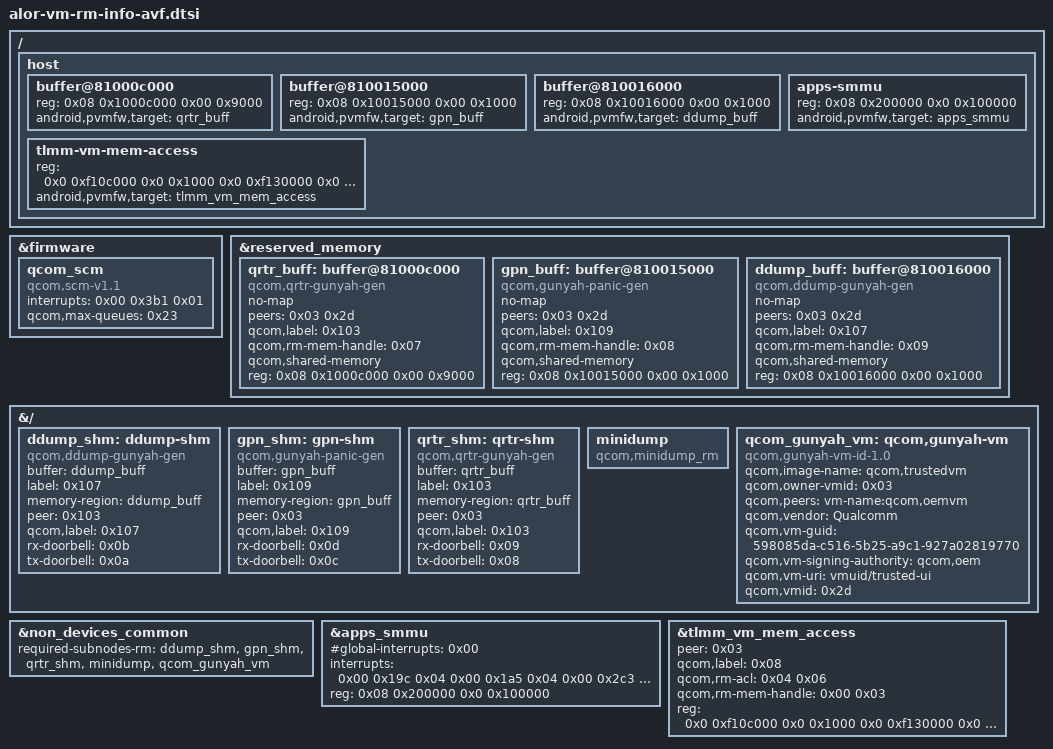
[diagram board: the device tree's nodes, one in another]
// SPDX-License-Identifier: BSD-3-Clause
/*
 * Copyright (c) Qualcomm Technologies, Inc. and/or its subsidiaries.
 */

/ {
	host {
		buffer@81000c000 {
			reg = <0x08 0x1000c000 0x00 0x9000>;
			android,pvmfw,target = <&qrtr_buff>;
		};

		buffer@810015000 {
			reg = <0x08 0x10015000 0x00 0x1000>;
			android,pvmfw,target = <&gpn_buff>;
		};

		buffer@810016000 {
			reg = <0x08 0x10016000 0x00 0x1000>;
			android,pvmfw,target = <&ddump_buff>;
		};

		apps-smmu {
			reg = <0x08 0x200000 0x0 0x100000>;
			android,pvmfw,target = <&apps_smmu>;
		};

		tlmm-vm-mem-access {
			reg = <0x0 0xf10c000 0x0 0x1000 0x0 0xf130000 0x0 0x1000 0x0 0xf131000 0x0 0x1000 0x0 0xf132000 0x0 0x1000 0x0 0xf133000 0x0 0x1000 0x0 0xf137000 0x0 0x1000 0x0 0xf144000 0x0 0x1000 0x0 0xf145000 0x0 0x1000 0x0 0xf146000 0x0 0x1000 0x0 0xf147000 0x0 0x1000 0x0 0xf156000 0x0 0x1000 0x0 0xf157000 0x0 0x1000 0x0 0xf158000 0x0 0x1000 0x0 0xf164000 0x0 0x1000 0x0 0xf180000 0x0 0x1000 0x0 0xf192000 0x0 0x1000 0x0 0xf1a1000 0x0 0x1000>;
			android,pvmfw,target = <&tlmm_vm_mem_access>;
		};
	};
};

&firmware {
	qcom_scm {
		compatible = "qcom,scm-v1.1", "qcom,scm";
		interrupts = <0x00 0x3b1 0x01>;
		qcom,max-queues = <0x23>;
	};

};

&reserved_memory {

	qrtr_buff: buffer@81000c000 {
		compatible = "qcom,qrtr-gunyah-gen";
		no-map;
		peers = <0x03 0x2d>;
		qcom,label = <0x103>;
		qcom,rm-mem-handle = <0x07>;
		qcom,shared-memory;
		reg = <0x08 0x1000c000 0x00 0x9000>;
	};

	gpn_buff: buffer@810015000 {
		compatible = "qcom,gunyah-panic-gen";
		no-map;
		peers = <0x03 0x2d>;
		qcom,label = <0x109>;
		qcom,rm-mem-handle = <0x08>;
		qcom,shared-memory;
		reg = <0x08 0x10015000 0x00 0x1000>;
	};

	ddump_buff: buffer@810016000 {
		compatible = "qcom,ddump-gunyah-gen";
		no-map;
		peers = <0x03 0x2d>;
		qcom,label = <0x107>;
		qcom,rm-mem-handle = <0x09>;
		qcom,shared-memory;
		reg = <0x08 0x10016000 0x00 0x1000>;
	};

};

&{/}  {
	ddump_shm: ddump-shm {
		buffer = <&ddump_buff>;
		compatible = "qcom,ddump-gunyah-gen", "qcom,gunyah-shm-doorbell";
		label = <0x107>;
		memory-region = <&ddump_buff>;
		peer = <0x103>;
		qcom,label = <0x107>;
		rx-doorbell = <0x0b>;
		tx-doorbell = <0x0a>;
	};

	gpn_shm: gpn-shm {
		buffer = <&gpn_buff>;
		compatible = "qcom,gunyah-panic-gen", "qcom,gunyah-shm-doorbell";
		label = <0x109>;
		memory-region = <&gpn_buff>;
		peer = <0x03>;
		qcom,label = <0x109>;
		rx-doorbell = <0x0d>;
		tx-doorbell = <0x0c>;
	};

	qrtr_shm: qrtr-shm {
		buffer = <&qrtr_buff>;
		compatible = "qcom,qrtr-gunyah-gen", "qcom,gunyah-shm-doorbell";
		label = <0x103>;
		memory-region = <&qrtr_buff>;
		peer = <0x03>;
		qcom,label = <0x103>;
		rx-doorbell = <0x09>;
		tx-doorbell = <0x08>;
	};

	minidump: minidump {
		compatible = "qcom,minidump_rm", "qcom,minidump-rm";
	};

	qcom_gunyah_vm: qcom,gunyah-vm {
		compatible = "qcom,gunyah-vm-id-1.0", "qcom,gunyah-vm-id";
		qcom,image-name = "qcom,trustedvm";
		qcom,owner-vmid = <0x03>;
		qcom,peers = "vm-name:qcom,oemvm";
		qcom,vendor = "Qualcomm";
		qcom,vm-guid = "598085da-c516-5b25-a9c1-927a02819770";
		qcom,vm-signing-authority = "qcom,oem";
		qcom,vm-uri = "vmuid/trusted-ui";
		qcom,vmid = <0x2d>;
	};
};

&non_devices_common {
		required-subnodes-rm = <&ddump_shm
				&gpn_shm
				&qrtr_shm
				&minidump
				&qcom_gunyah_vm>;
};

&apps_smmu {
	#global-interrupts = <0x00>;
	interrupts = <0x00 0x19c 0x04 0x00 0x1a5 0x04 0x00 0x2c3 0x04 0x00 0x1a7 0x04 0x00 0x1a8 0x04 0x00 0x1a9 0x04>;
	reg = <0x08 0x200000 0x0 0x100000>;
};

&tlmm_vm_mem_access {
	peer = <0x03>;
	qcom,label = <0x08>;
	qcom,rm-acl = <0x04 0x06>;
	qcom,rm-mem-handle = <0x00 0x03>;
	reg = <0x0 0xf10c000 0x0 0x1000 0x0 0xf130000 0x0 0x1000 0x0 0xf131000 0x0 0x1000 0x0 0xf132000 0x0 0x1000 0x0 0xf133000 0x0 0x1000 0x0 0xf137000 0x0 0x1000 0x0 0xf144000 0x0 0x1000 0x0 0xf145000 0x0 0x1000 0x0 0xf146000 0x0 0x1000 0x0 0xf147000 0x0 0x1000 0x0 0xf156000 0x0 0x1000 0x0 0xf157000 0x0 0x1000 0x0 0xf158000 0x0 0x1000 0x0 0xf164000 0x0 0x1000 0x0 0xf180000 0x0 0x1000 0x0 0xf192000 0x0 0x1000 0x0 0xf1a1000 0x0 0x1000>;
};
